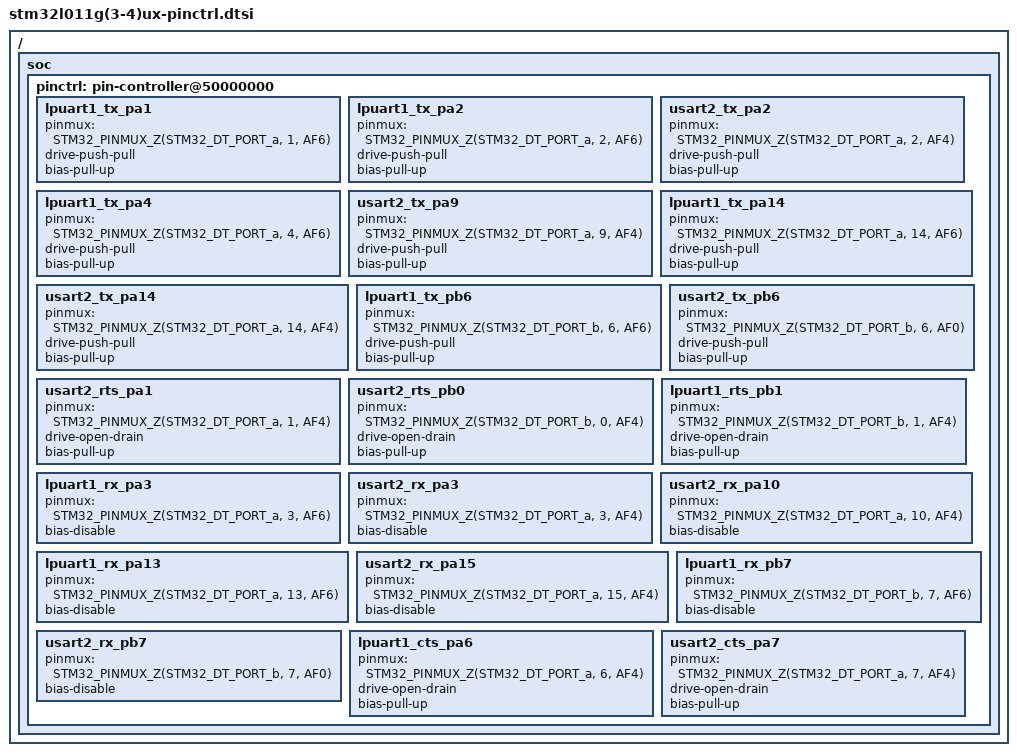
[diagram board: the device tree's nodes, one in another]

/*
 * NOTE: Autogenerated file using stm32_pinctrl_gen.py
 *
 * SPDX-License-Identifier: Apache-2.0
 */

#include <dt-bindings/pinctrl/stm32-pinctrl.h>

/ {
	soc {
		pinctrl: pin-controller@50000000 {
			/* UART_TX */
			lpuart1_tx_pa1: lpuart1_tx_pa1 {
				pinmux = <STM32_PINMUX_Z(STM32_DT_PORT_a, 1, AF6)>;
				drive-push-pull;
				bias-pull-up;
			};

			lpuart1_tx_pa1: lpuart1_tx_pa1 {
				pinmux = <STM32_PINMUX_Z(STM32_DT_PORT_a, 1, AF6)>;
				drive-push-pull;
				bias-pull-up;
			};

			lpuart1_tx_pa2: lpuart1_tx_pa2 {
				pinmux = <STM32_PINMUX_Z(STM32_DT_PORT_a, 2, AF6)>;
				drive-push-pull;
				bias-pull-up;
			};

			lpuart1_tx_pa2: lpuart1_tx_pa2 {
				pinmux = <STM32_PINMUX_Z(STM32_DT_PORT_a, 2, AF6)>;
				drive-push-pull;
				bias-pull-up;
			};

			usart2_tx_pa2: usart2_tx_pa2 {
				pinmux = <STM32_PINMUX_Z(STM32_DT_PORT_a, 2, AF4)>;
				drive-push-pull;
				bias-pull-up;
			};

			lpuart1_tx_pa4: lpuart1_tx_pa4 {
				pinmux = <STM32_PINMUX_Z(STM32_DT_PORT_a, 4, AF6)>;
				drive-push-pull;
				bias-pull-up;
			};

			lpuart1_tx_pa4: lpuart1_tx_pa4 {
				pinmux = <STM32_PINMUX_Z(STM32_DT_PORT_a, 4, AF6)>;
				drive-push-pull;
				bias-pull-up;
			};

			usart2_tx_pa9: usart2_tx_pa9 {
				pinmux = <STM32_PINMUX_Z(STM32_DT_PORT_a, 9, AF4)>;
				drive-push-pull;
				bias-pull-up;
			};

			lpuart1_tx_pa14: lpuart1_tx_pa14 {
				pinmux = <STM32_PINMUX_Z(STM32_DT_PORT_a, 14, AF6)>;
				drive-push-pull;
				bias-pull-up;
			};

			lpuart1_tx_pa14: lpuart1_tx_pa14 {
				pinmux = <STM32_PINMUX_Z(STM32_DT_PORT_a, 14, AF6)>;
				drive-push-pull;
				bias-pull-up;
			};

			usart2_tx_pa14: usart2_tx_pa14 {
				pinmux = <STM32_PINMUX_Z(STM32_DT_PORT_a, 14, AF4)>;
				drive-push-pull;
				bias-pull-up;
			};

			lpuart1_tx_pb6: lpuart1_tx_pb6 {
				pinmux = <STM32_PINMUX_Z(STM32_DT_PORT_b, 6, AF6)>;
				drive-push-pull;
				bias-pull-up;
			};

			lpuart1_tx_pb6: lpuart1_tx_pb6 {
				pinmux = <STM32_PINMUX_Z(STM32_DT_PORT_b, 6, AF6)>;
				drive-push-pull;
				bias-pull-up;
			};

			usart2_tx_pb6: usart2_tx_pb6 {
				pinmux = <STM32_PINMUX_Z(STM32_DT_PORT_b, 6, AF0)>;
				drive-push-pull;
				bias-pull-up;
			};


			/* UART_RTS */
			usart2_rts_pa1: usart2_rts_pa1 {
				pinmux = <STM32_PINMUX_Z(STM32_DT_PORT_a, 1, AF4)>;
				drive-open-drain;
				bias-pull-up;
			};

			usart2_rts_pb0: usart2_rts_pb0 {
				pinmux = <STM32_PINMUX_Z(STM32_DT_PORT_b, 0, AF4)>;
				drive-open-drain;
				bias-pull-up;
			};

			lpuart1_rts_pb1: lpuart1_rts_pb1 {
				pinmux = <STM32_PINMUX_Z(STM32_DT_PORT_b, 1, AF4)>;
				drive-open-drain;
				bias-pull-up;
			};

			lpuart1_rts_pb1: lpuart1_rts_pb1 {
				pinmux = <STM32_PINMUX_Z(STM32_DT_PORT_b, 1, AF4)>;
				drive-open-drain;
				bias-pull-up;
			};


			/* UART_RX */
			lpuart1_rx_pa3: lpuart1_rx_pa3 {
				pinmux = <STM32_PINMUX_Z(STM32_DT_PORT_a, 3, AF6)>;
				bias-disable;
			};

			lpuart1_rx_pa3: lpuart1_rx_pa3 {
				pinmux = <STM32_PINMUX_Z(STM32_DT_PORT_a, 3, AF6)>;
				bias-disable;
			};

			usart2_rx_pa3: usart2_rx_pa3 {
				pinmux = <STM32_PINMUX_Z(STM32_DT_PORT_a, 3, AF4)>;
				bias-disable;
			};

			usart2_rx_pa10: usart2_rx_pa10 {
				pinmux = <STM32_PINMUX_Z(STM32_DT_PORT_a, 10, AF4)>;
				bias-disable;
			};

			lpuart1_rx_pa13: lpuart1_rx_pa13 {
				pinmux = <STM32_PINMUX_Z(STM32_DT_PORT_a, 13, AF6)>;
				bias-disable;
			};

			lpuart1_rx_pa13: lpuart1_rx_pa13 {
				pinmux = <STM32_PINMUX_Z(STM32_DT_PORT_a, 13, AF6)>;
				bias-disable;
			};

			usart2_rx_pa15: usart2_rx_pa15 {
				pinmux = <STM32_PINMUX_Z(STM32_DT_PORT_a, 15, AF4)>;
				bias-disable;
			};

			lpuart1_rx_pb7: lpuart1_rx_pb7 {
				pinmux = <STM32_PINMUX_Z(STM32_DT_PORT_b, 7, AF6)>;
				bias-disable;
			};

			lpuart1_rx_pb7: lpuart1_rx_pb7 {
				pinmux = <STM32_PINMUX_Z(STM32_DT_PORT_b, 7, AF6)>;
				bias-disable;
			};

			usart2_rx_pb7: usart2_rx_pb7 {
				pinmux = <STM32_PINMUX_Z(STM32_DT_PORT_b, 7, AF0)>;
				bias-disable;
			};


			/* UART_CTS */
			lpuart1_cts_pa6: lpuart1_cts_pa6 {
				pinmux = <STM32_PINMUX_Z(STM32_DT_PORT_a, 6, AF4)>;
				drive-open-drain;
				bias-pull-up;
			};

			lpuart1_cts_pa6: lpuart1_cts_pa6 {
				pinmux = <STM32_PINMUX_Z(STM32_DT_PORT_a, 6, AF4)>;
				drive-open-drain;
				bias-pull-up;
			};

			usart2_cts_pa7: usart2_cts_pa7 {
				pinmux = <STM32_PINMUX_Z(STM32_DT_PORT_a, 7, AF4)>;
				drive-open-drain;
				bias-pull-up;
			};

		};
	};
};
